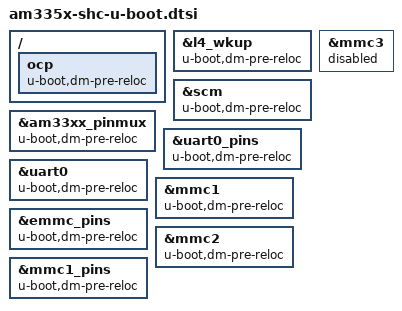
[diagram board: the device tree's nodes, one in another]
// SPDX-License-Identifier: GPL-2.0
/*
 * Copyright (C) 2019 Heiko Schocher <hs@denx.de>
 */

/ {
	ocp {
		u-boot,dm-pre-reloc;
	};
};

&l4_wkup {
	u-boot,dm-pre-reloc;
};

&scm {
	u-boot,dm-pre-reloc;
};

&am33xx_pinmux {
	u-boot,dm-pre-reloc;
};

&uart0_pins {
	u-boot,dm-pre-reloc;
};

&uart0 {
	u-boot,dm-pre-reloc;
};

&mmc1 {
	u-boot,dm-pre-reloc;
};

&emmc_pins {
	u-boot,dm-pre-reloc;
};

&mmc2 {
	u-boot,dm-pre-reloc;
};

&mmc1_pins {
	u-boot,dm-pre-reloc;
};

&mmc3 {
	status = "disabled";
};
